# cslr_edma3cc register map
Vendor: Texas Instruments
Peripheral module from a debugger description file (folder TCI6484_C6457).
Registers are 32-bit, read-write, reset 0x0 unless marked. A register's access mark holds for its fields unless they carry their own. Offsets are as the file gives them; lines under a group give offsets from that group; [hi:lo] are bit positions; {n}, {i} and the like mark numbered series; 'fields as' and 'values as' point back to an identical list; <NAME> marks a mode.

## EDMA3CC — Enhanced DMA Channel Controller Module.
0x00 PID ro reset 0x40018B00 — Peripheral Revision
  [31:0] PID — Peripheral identifier uniquely identifies the EDMA3CC and the specific revision of the EDMA3CC
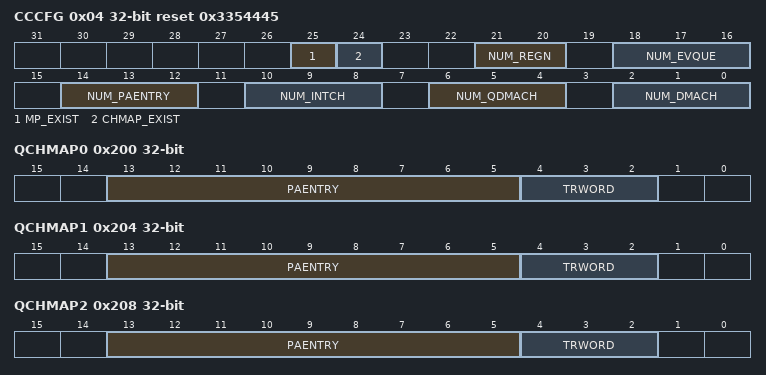
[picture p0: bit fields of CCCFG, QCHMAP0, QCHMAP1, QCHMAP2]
0x04 CCCFG access not given reset 0x3354445 — CC Configuration
  [25] MP_EXIST ro — Memory Protection Existence
    1=INCLUDED (Memory protection logic included)
  [24] CHMAP_EXIST ro — Channel Mapping Existence
    1=INCLUDED (Channel mapping logic included)
  [21:20] NUM_REGN ro — Number of MP and Shadow regions
    3=8 Regions
  [18:16] NUM_EVQUE ro — Number of Queues/Number of TCs
    5=6 TC/Event Queue
  [14:12] NUM_PAENTRY ro — Number of PaRAM entries
    4=256 Entries
  [10:8] NUM_INTCH ro — Number of Interrupt Channels
    4=64 Interrupt Channels
  [6:4] NUM_QDMACH ro — Number of QDMA Channels
    4=8 QDMA Channels
  [2:0] NUM_DMACH ro — Number of DMA Channels
    5=64 DMA Channels
0x100 DCHMAP0 access not given — DMA Channel Mapping to PaRAM{DCHMAP}
  [13:5] PAENTRY rw — Points to the PaRAM Entry number for the DMA Channel N
0x104 DCHMAP1 access not given — DMA Channel Mapping to PaRAM{DCHMAP}
  fields as DCHMAP0
0x108 DCHMAP2 access not given — DMA Channel Mapping to PaRAM{DCHMAP}
  fields as DCHMAP0
0x10C DCHMAP3 access not given — DMA Channel Mapping to PaRAM{DCHMAP}
  fields as DCHMAP0
0x110 DCHMAP4 access not given — DMA Channel Mapping to PaRAM{DCHMAP}
  fields as DCHMAP0
0x114 DCHMAP5 access not given — DMA Channel Mapping to PaRAM{DCHMAP}
  fields as DCHMAP0
0x118 DCHMAP6 access not given — DMA Channel Mapping to PaRAM{DCHMAP}
  fields as DCHMAP0
0x11C DCHMAP7 access not given — DMA Channel Mapping to PaRAM{DCHMAP}
  fields as DCHMAP0
0x120 DCHMAP8 access not given — DMA Channel Mapping to PaRAM{DCHMAP}
  fields as DCHMAP0
0x124 DCHMAP9 access not given — DMA Channel Mapping to PaRAM{DCHMAP}
  fields as DCHMAP0
0x128 DCHMAP10 access not given — DMA Channel Mapping to PaRAM{DCHMAP}
  fields as DCHMAP0
0x12C DCHMAP11 access not given — DMA Channel Mapping to PaRAM{DCHMAP}
  fields as DCHMAP0
0x130 DCHMAP12 access not given — DMA Channel Mapping to PaRAM{DCHMAP}
  fields as DCHMAP0
0x134 DCHMAP13 access not given — DMA Channel Mapping to PaRAM{DCHMAP}
  fields as DCHMAP0
0x138 DCHMAP14 access not given — DMA Channel Mapping to PaRAM{DCHMAP}
  fields as DCHMAP0
0x13C DCHMAP15 access not given — DMA Channel Mapping to PaRAM{DCHMAP}
  fields as DCHMAP0
0x140 DCHMAP16 access not given — DMA Channel Mapping to PaRAM{DCHMAP}
  fields as DCHMAP0
0x144 DCHMAP17 access not given — DMA Channel Mapping to PaRAM{DCHMAP}
  fields as DCHMAP0
0x148 DCHMAP18 access not given — DMA Channel Mapping to PaRAM{DCHMAP}
  fields as DCHMAP0
0x14C DCHMAP19 access not given — DMA Channel Mapping to PaRAM{DCHMAP}
  fields as DCHMAP0
0x150 DCHMAP20 access not given — DMA Channel Mapping to PaRAM{DCHMAP}
  fields as DCHMAP0
0x154 DCHMAP21 access not given — DMA Channel Mapping to PaRAM{DCHMAP}
  fields as DCHMAP0
0x158 DCHMAP22 access not given — DMA Channel Mapping to PaRAM{DCHMAP}
  fields as DCHMAP0
0x15C DCHMAP23 access not given — DMA Channel Mapping to PaRAM{DCHMAP}
  fields as DCHMAP0
0x160 DCHMAP24 access not given — DMA Channel Mapping to PaRAM{DCHMAP}
  fields as DCHMAP0
0x164 DCHMAP25 access not given — DMA Channel Mapping to PaRAM{DCHMAP}
  fields as DCHMAP0
0x168 DCHMAP26 access not given — DMA Channel Mapping to PaRAM{DCHMAP}
  fields as DCHMAP0
0x16C DCHMAP27 access not given — DMA Channel Mapping to PaRAM{DCHMAP}
  fields as DCHMAP0
0x170 DCHMAP28 access not given — DMA Channel Mapping to PaRAM{DCHMAP}
  fields as DCHMAP0
0x174 DCHMAP29 access not given — DMA Channel Mapping to PaRAM{DCHMAP}
  fields as DCHMAP0
0x178 DCHMAP30 access not given — DMA Channel Mapping to PaRAM{DCHMAP}
  fields as DCHMAP0
0x17C DCHMAP31 access not given — DMA Channel Mapping to PaRAM{DCHMAP}
  fields as DCHMAP0
0x180 DCHMAP32 access not given — DMA Channel Mapping to PaRAM{DCHMAP}
  fields as DCHMAP0
0x184 DCHMAP33 access not given — DMA Channel Mapping to PaRAM{DCHMAP}
  fields as DCHMAP0
0x188 DCHMAP34 access not given — DMA Channel Mapping to PaRAM{DCHMAP}
  fields as DCHMAP0
0x18C DCHMAP35 access not given — DMA Channel Mapping to PaRAM{DCHMAP}
  fields as DCHMAP0
0x190 DCHMAP36 access not given — DMA Channel Mapping to PaRAM{DCHMAP}
  fields as DCHMAP0
0x194 DCHMAP37 access not given — DMA Channel Mapping to PaRAM{DCHMAP}
  fields as DCHMAP0
0x198 DCHMAP38 access not given — DMA Channel Mapping to PaRAM{DCHMAP}
  fields as DCHMAP0
0x19C DCHMAP39 access not given — DMA Channel Mapping to PaRAM{DCHMAP}
  fields as DCHMAP0
0x1A0 DCHMAP40 access not given — DMA Channel Mapping to PaRAM{DCHMAP}
  fields as DCHMAP0
0x1A4 DCHMAP41 access not given — DMA Channel Mapping to PaRAM{DCHMAP}
  fields as DCHMAP0
0x1A8 DCHMAP42 access not given — DMA Channel Mapping to PaRAM{DCHMAP}
  fields as DCHMAP0
0x1AC DCHMAP43 access not given — DMA Channel Mapping to PaRAM{DCHMAP}
  fields as DCHMAP0
0x1B0 DCHMAP44 access not given — DMA Channel Mapping to PaRAM{DCHMAP}
  fields as DCHMAP0
0x1B4 DCHMAP45 access not given — DMA Channel Mapping to PaRAM{DCHMAP}
  fields as DCHMAP0
0x1B8 DCHMAP46 access not given — DMA Channel Mapping to PaRAM{DCHMAP}
  fields as DCHMAP0
0x1BC DCHMAP47 access not given — DMA Channel Mapping to PaRAM{DCHMAP}
  fields as DCHMAP0
0x1C0 DCHMAP48 access not given — DMA Channel Mapping to PaRAM{DCHMAP}
  fields as DCHMAP0
0x1C4 DCHMAP49 access not given — DMA Channel Mapping to PaRAM{DCHMAP}
  fields as DCHMAP0
0x1C8 DCHMAP50 access not given — DMA Channel Mapping to PaRAM{DCHMAP}
  fields as DCHMAP0
0x1CC DCHMAP51 access not given — DMA Channel Mapping to PaRAM{DCHMAP}
  fields as DCHMAP0
0x1D0 DCHMAP52 access not given — DMA Channel Mapping to PaRAM{DCHMAP}
  fields as DCHMAP0
0x1D4 DCHMAP53 access not given — DMA Channel Mapping to PaRAM{DCHMAP}
  fields as DCHMAP0
0x1D8 DCHMAP54 access not given — DMA Channel Mapping to PaRAM{DCHMAP}
  fields as DCHMAP0
0x1DC DCHMAP55 access not given — DMA Channel Mapping to PaRAM{DCHMAP}
  fields as DCHMAP0
0x1E0 DCHMAP56 access not given — DMA Channel Mapping to PaRAM{DCHMAP}
  fields as DCHMAP0
0x1E4 DCHMAP57 access not given — DMA Channel Mapping to PaRAM{DCHMAP}
  fields as DCHMAP0
0x1E8 DCHMAP58 access not given — DMA Channel Mapping to PaRAM{DCHMAP}
  fields as DCHMAP0
0x1EC DCHMAP59 access not given — DMA Channel Mapping to PaRAM{DCHMAP}
  fields as DCHMAP0
0x1F0 DCHMAP60 access not given — DMA Channel Mapping to PaRAM{DCHMAP}
  fields as DCHMAP0
0x1F4 DCHMAP61 access not given — DMA Channel Mapping to PaRAM{DCHMAP}
  fields as DCHMAP0
0x1F8 DCHMAP62 access not given — DMA Channel Mapping to PaRAM{DCHMAP}
  fields as DCHMAP0
0x1FC DCHMAP63 access not given — DMA Channel Mapping to PaRAM{DCHMAP}
  fields as DCHMAP0
0x200 QCHMAP0 access not given — QDMA Channel Mapping to PaRAM{QCHMAP}
  [13:5] PAENTRY rw — Points to the PaRAM Entry number for the QDMA Channel N
  [4:2] TRWORD rw — Points to the specific trigger word of the PaRAM set defined by PAENTRY. A write to the trigger word results in a QDMA event being recognized
0x204 QCHMAP1 access not given — QDMA Channel Mapping to PaRAM{QCHMAP}
  fields as QCHMAP0
0x208 QCHMAP2 access not given — QDMA Channel Mapping to PaRAM{QCHMAP}
  fields as QCHMAP0
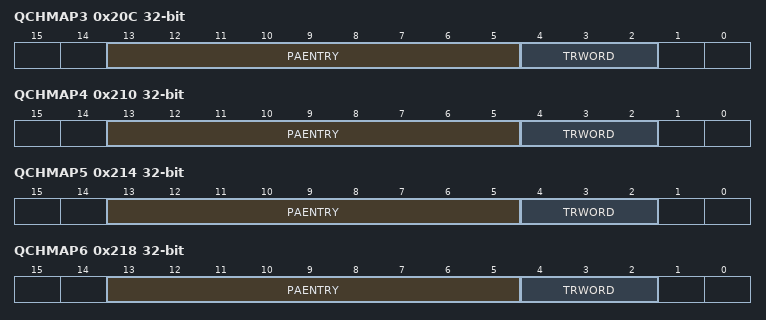
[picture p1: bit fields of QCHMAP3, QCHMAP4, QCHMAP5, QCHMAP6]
0x20C QCHMAP3 access not given — QDMA Channel Mapping to PaRAM{QCHMAP}
  fields as QCHMAP0
0x210 QCHMAP4 access not given — QDMA Channel Mapping to PaRAM{QCHMAP}
  fields as QCHMAP0
0x214 QCHMAP5 access not given — QDMA Channel Mapping to PaRAM{QCHMAP}
  fields as QCHMAP0
0x218 QCHMAP6 access not given — QDMA Channel Mapping to PaRAM{QCHMAP}
  fields as QCHMAP0
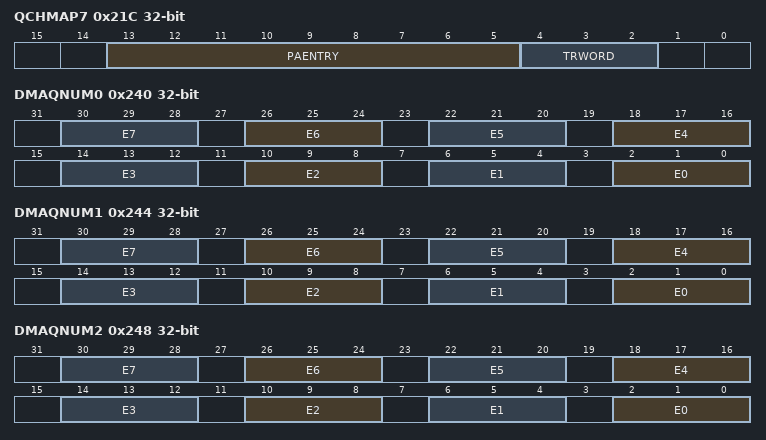
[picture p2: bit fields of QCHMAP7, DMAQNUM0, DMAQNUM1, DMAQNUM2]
0x21C QCHMAP7 access not given — QDMA Channel Mapping to PaRAM{QCHMAP}
  fields as QCHMAP0
0x240 DMAQNUM0 access not given — DMA Queue Number{DMAQNUM}
  [4n+2:4n] E{n} rw (n=0..7) — Event number = (ArrayIndex * 8) + {n}
0x244 DMAQNUM1 access not given — DMA Queue Number{DMAQNUM}
  [4n+2:4n] E{n} rw (n=0..7) — Event number = (ArrayIndex * 8) + {n}
0x248 DMAQNUM2 access not given — DMA Queue Number{DMAQNUM}
  [4n+2:4n] E{n} rw (n=0..7) — Event number = (ArrayIndex * 8) + {n}
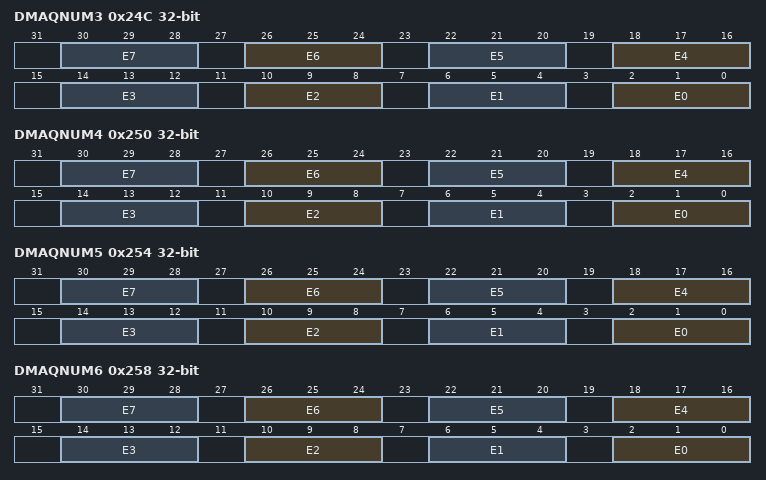
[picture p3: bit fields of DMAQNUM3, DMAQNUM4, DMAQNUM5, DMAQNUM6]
0x24C DMAQNUM3 access not given — DMA Queue Number{DMAQNUM}
  [4n+2:4n] E{n} rw (n=0..7) — Event number = (ArrayIndex * 8) + {n}
0x250 DMAQNUM4 access not given — DMA Queue Number{DMAQNUM}
  [4n+2:4n] E{n} rw (n=0..7) — Event number = (ArrayIndex * 8) + {n}
0x254 DMAQNUM5 access not given — DMA Queue Number{DMAQNUM}
  [4n+2:4n] E{n} rw (n=0..7) — Event number = (ArrayIndex * 8) + {n}
0x258 DMAQNUM6 access not given — DMA Queue Number{DMAQNUM}
  [4n+2:4n] E{n} rw (n=0..7) — Event number = (ArrayIndex * 8) + {n}
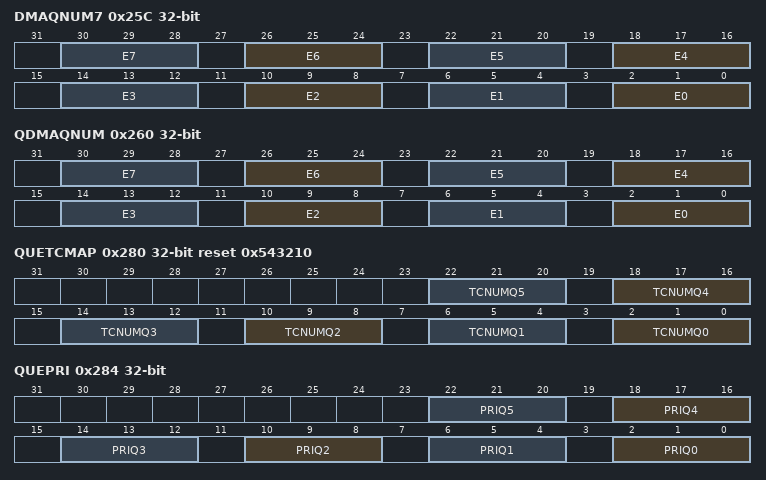
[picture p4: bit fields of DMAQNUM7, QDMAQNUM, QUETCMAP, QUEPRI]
0x25C DMAQNUM7 access not given — DMA Queue Number{DMAQNUM}
  [4n+2:4n] E{n} rw (n=0..7) — Event number = (ArrayIndex * 8) + {n}
0x260 QDMAQNUM access not given — QDMA Queue Number
  [4n+2:4n] E{n} rw (n=0..7) — Event number {n}
0x280 QUETCMAP access not given reset 0x543210 — Queue-to-TC Mapping Register
  [4n+2:4n] TCNUMQ{n} rw (n=0..5) — TC number for queue {n}.
0x284 QUEPRI access not given — Queue Priority
  [4n+2:4n] PRIQ{n} rw (n=0..5) — Priority level for Queue {n}
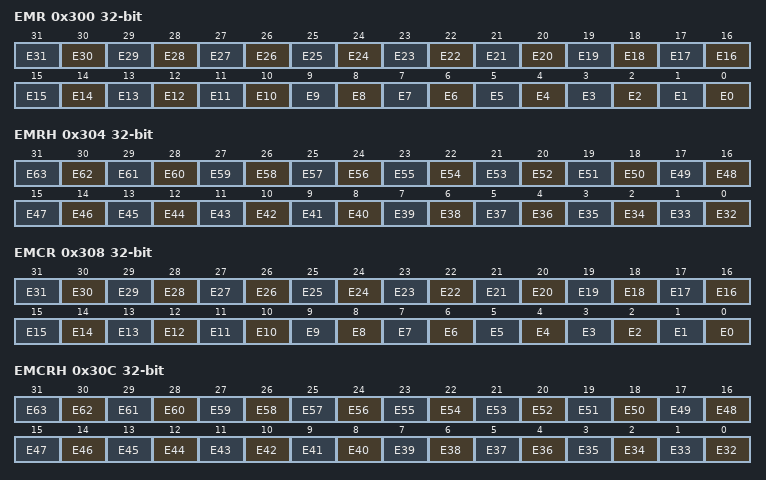
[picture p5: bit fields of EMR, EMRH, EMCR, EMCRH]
0x300 EMR ro — Event Miss Register
  [n] E{n} (n=0..31) — Event missed number {n}
0x304 EMRH ro — Event Miss Register High
  [n-32] E{n} (n=32..63) — Event missed number {n}
0x308 EMCR wo — Event Miss Clear Register
  [all] fields
    1=CLEAR
  [n] E{n} (n=0..31) — Event missed {n} clear
0x30C EMCRH wo — Event Miss Clear Register High
  [all] fields
    1=CLEAR
  [n-32] E{n} (n=32..63) — Event missed {n} clear
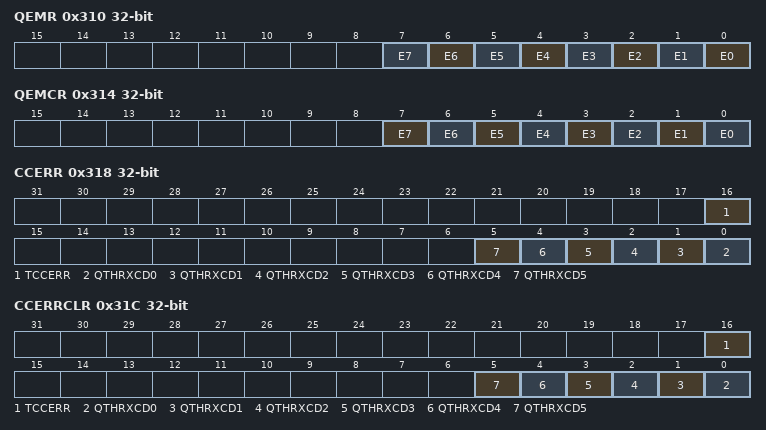
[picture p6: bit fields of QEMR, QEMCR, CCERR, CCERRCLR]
0x310 QEMR access not given — QDMA Event Miss Register
  [n] E{n} ro (n=0..7) — Event miss event {n}
0x314 QEMCR access not given — QDMA Event Miss Register
  [all] fields
    1=CLEAR
  [7] E7 wo — QDMA miss event 7clear
  [n] E{n} wo (n=0..6) — QDMA miss event {n} clear
0x318 CCERR access not given — CC Error Register
  [16] TCCERR ro — Transfer completion code error
  [n] QTHRXCD{n} ro (n=0..5) — Queue Threshold Error for Queue {n}
0x31C CCERRCLR access not given — CC Error Clear Register
  [all] fields
    1=CLEAR
  [16] TCCERR wo — Transfer completion code error clear
  [n] QTHRXCD{n} wo (n=0..5) — Queue Threshold Error Clear for Queue {n}
0x320 EEVAL access not given — Error Evaluation Register
  [0] EVAL wo — Error interrupt Evaluate
    1=EVAL (Error Interrupt Evaluate)
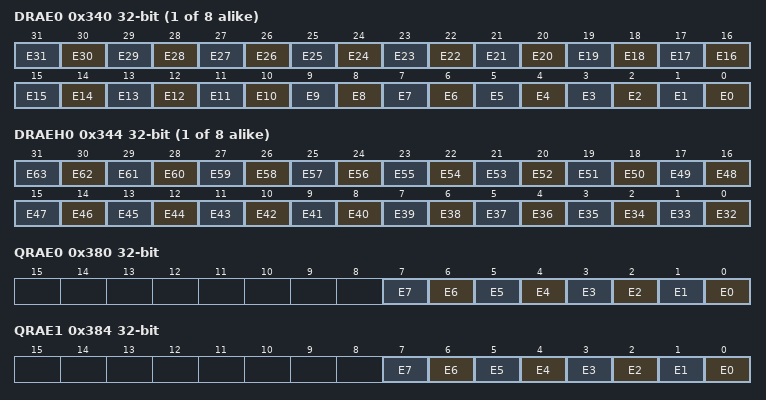
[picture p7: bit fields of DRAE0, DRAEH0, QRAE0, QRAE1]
{0x340+8i} DRAE{i} (i=0..7) — DMA Region Access Enable
  [n] E{n} (n=0..31) — DMA region access enable for bit {n}/channel {n} in region m (m = 0 to 7)
{0x344+8i} DRAEH{i} (i=0..7) — DMA Region Access Enable High
  [n-32] E{n} (n=32..63) — DMA region access enable for bit {n}/channel {n} in region m (m = 0 to 7)
0x380 QRAE0 access not given — QDMA Region Access Enable{QRAE}
  [n] E{n} rw (n=0..7) — QDMA region access enable for bit {n}/channel {n} in region m (m = 0 to 7)
0x384 QRAE1 access not given — QDMA Region Access Enable{QRAE}
  fields as QRAE0
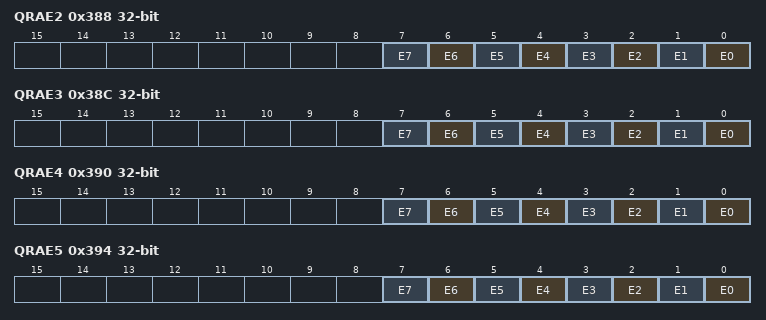
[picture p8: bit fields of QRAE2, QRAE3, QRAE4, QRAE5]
0x388 QRAE2 access not given — QDMA Region Access Enable{QRAE}
  fields as QRAE0
0x38C QRAE3 access not given — QDMA Region Access Enable{QRAE}
  fields as QRAE0
0x390 QRAE4 access not given — QDMA Region Access Enable{QRAE}
  fields as QRAE0
0x394 QRAE5 access not given — QDMA Region Access Enable{QRAE}
  fields as QRAE0
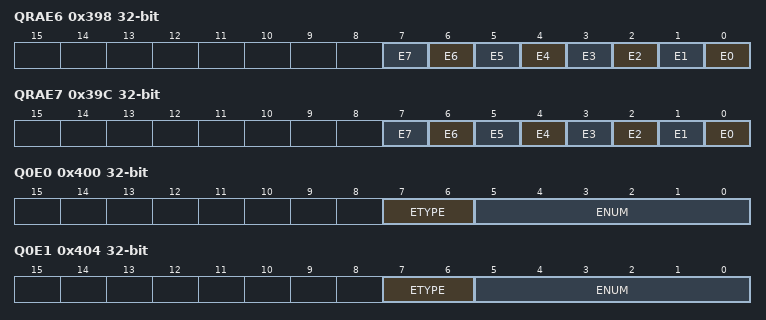
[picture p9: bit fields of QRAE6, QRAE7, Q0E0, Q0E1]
0x398 QRAE6 access not given — QDMA Region Access Enable{QRAE}
  fields as QRAE0
0x39C QRAE7 access not given — QDMA Region Access Enable{QRAE}
  fields as QRAE0
0x400 Q0E0 ro — Event Entry{EVT_ENTRY}
  [7:6] ETYPE — Event Type
    0=EVENT (Event Triggered via ER); 1=MANUAL (Manual Triggered via ESR); 2=CHAIN (Chain Triggered via CER); 3=AUTO (Auto Triggered via QER)
  [5:0] ENUM — Event Number (0-63)/(0-7)
0x404 Q0E1 ro — Event Entry{EVT_ENTRY}
  fields as Q0E0
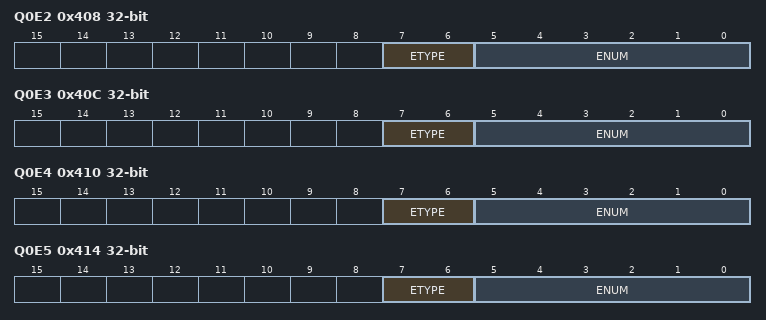
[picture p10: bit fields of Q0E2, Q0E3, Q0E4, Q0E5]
0x408 Q0E2 ro — Event Entry{EVT_ENTRY}
  fields as Q0E0
0x40C Q0E3 ro — Event Entry{EVT_ENTRY}
  fields as Q0E0
0x410 Q0E4 ro — Event Entry{EVT_ENTRY}
  fields as Q0E0
0x414 Q0E5 ro — Event Entry{EVT_ENTRY}
  fields as Q0E0
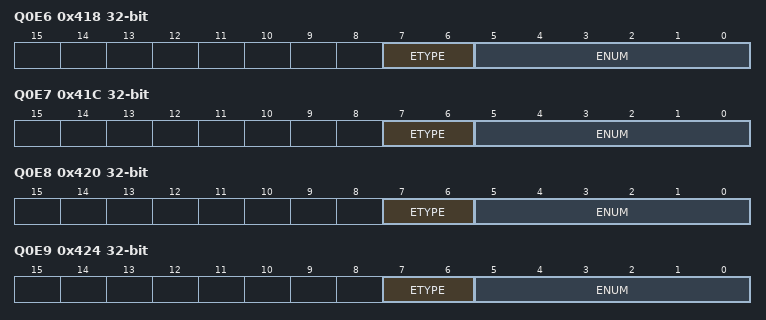
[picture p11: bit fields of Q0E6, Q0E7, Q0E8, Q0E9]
0x418 Q0E6 ro — Event Entry{EVT_ENTRY}
  fields as Q0E0
0x41C Q0E7 ro — Event Entry{EVT_ENTRY}
  fields as Q0E0
0x420 Q0E8 ro — Event Entry{EVT_ENTRY}
  fields as Q0E0
0x424 Q0E9 ro — Event Entry{EVT_ENTRY}
  fields as Q0E0
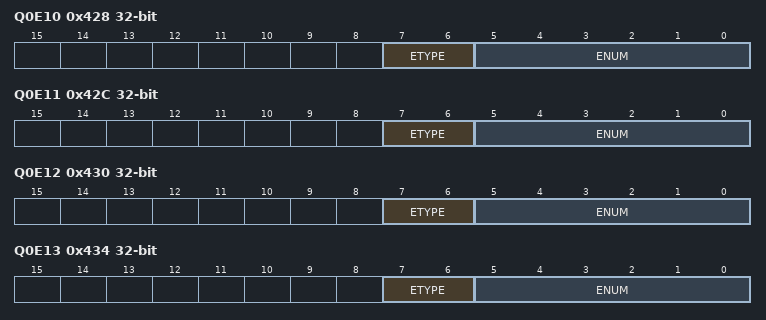
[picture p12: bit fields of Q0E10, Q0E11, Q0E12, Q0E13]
0x428 Q0E10 ro — Event Entry{EVT_ENTRY}
  fields as Q0E0
0x42C Q0E11 ro — Event Entry{EVT_ENTRY}
  fields as Q0E0
0x430 Q0E12 ro — Event Entry{EVT_ENTRY}
  fields as Q0E0
0x434 Q0E13 ro — Event Entry{EVT_ENTRY}
  fields as Q0E0
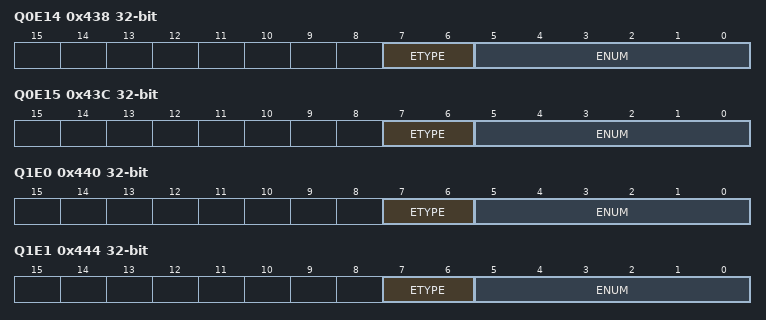
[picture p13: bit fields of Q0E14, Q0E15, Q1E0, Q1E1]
0x438 Q0E14 ro — Event Entry{EVT_ENTRY}
  fields as Q0E0
0x43C Q0E15 ro — Event Entry{EVT_ENTRY}
  fields as Q0E0
0x440 Q1E0 ro — Event Entry{EVT_ENTRY}
  fields as Q0E0
0x444 Q1E1 ro — Event Entry{EVT_ENTRY}
  fields as Q0E0
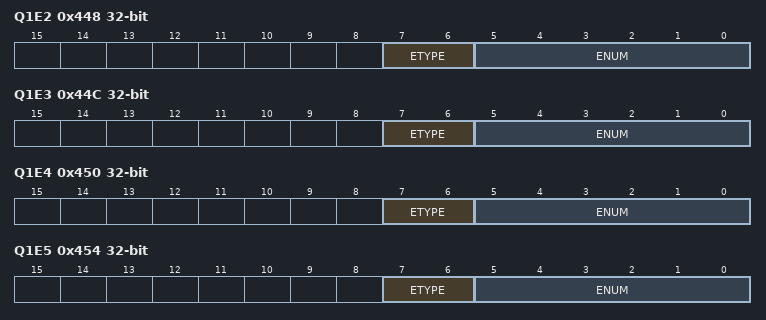
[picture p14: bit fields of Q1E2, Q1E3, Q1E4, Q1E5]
0x448 Q1E2 ro — Event Entry{EVT_ENTRY}
  fields as Q0E0
0x44C Q1E3 ro — Event Entry{EVT_ENTRY}
  fields as Q0E0
0x450 Q1E4 ro — Event Entry{EVT_ENTRY}
  fields as Q0E0
0x454 Q1E5 ro — Event Entry{EVT_ENTRY}
  fields as Q0E0
0x458 Q1E6 ro — Event Entry{EVT_ENTRY}
  fields as Q0E0
0x45C Q1E7 ro — Event Entry{EVT_ENTRY}
  fields as Q0E0
0x460 Q1E8 ro — Event Entry{EVT_ENTRY}
  fields as Q0E0
0x464 Q1E9 ro — Event Entry{EVT_ENTRY}
  fields as Q0E0
0x468 Q1E10 ro — Event Entry{EVT_ENTRY}
  fields as Q0E0
0x46C Q1E11 ro — Event Entry{EVT_ENTRY}
  fields as Q0E0
0x470 Q1E12 ro — Event Entry{EVT_ENTRY}
  fields as Q0E0
0x474 Q1E13 ro — Event Entry{EVT_ENTRY}
  fields as Q0E0
0x478 Q1E14 ro — Event Entry{EVT_ENTRY}
  fields as Q0E0
0x47C Q1E15 ro — Event Entry{EVT_ENTRY}
  fields as Q0E0
0x480 Q2E0 ro — Event Entry{EVT_ENTRY}
  fields as Q0E0
0x484 Q2E1 ro — Event Entry{EVT_ENTRY}
  fields as Q0E0
0x488 Q2E2 ro — Event Entry{EVT_ENTRY}
  fields as Q0E0
0x48C Q2E3 ro — Event Entry{EVT_ENTRY}
  fields as Q0E0
0x490 Q2E4 ro — Event Entry{EVT_ENTRY}
  fields as Q0E0
0x494 Q2E5 ro — Event Entry{EVT_ENTRY}
  fields as Q0E0
0x498 Q2E6 ro — Event Entry{EVT_ENTRY}
  fields as Q0E0
0x49C Q2E7 ro — Event Entry{EVT_ENTRY}
  fields as Q0E0
0x4A0 Q2E8 ro — Event Entry{EVT_ENTRY}
  fields as Q0E0
0x4A4 Q2E9 ro — Event Entry{EVT_ENTRY}
  fields as Q0E0
0x4A8 Q2E10 ro — Event Entry{EVT_ENTRY}
  fields as Q0E0
0x4AC Q2E11 ro — Event Entry{EVT_ENTRY}
  fields as Q0E0
0x4B0 Q2E12 ro — Event Entry{EVT_ENTRY}
  fields as Q0E0
0x4B4 Q2E13 ro — Event Entry{EVT_ENTRY}
  fields as Q0E0
0x4B8 Q2E14 ro — Event Entry{EVT_ENTRY}
  fields as Q0E0
0x4BC Q2E15 ro — Event Entry{EVT_ENTRY}
  fields as Q0E0
0x4C0 Q3E0 ro — Event Entry{EVT_ENTRY}
  fields as Q0E0
0x4C4 Q3E1 ro — Event Entry{EVT_ENTRY}
  fields as Q0E0
0x4C8 Q3E2 ro — Event Entry{EVT_ENTRY}
  fields as Q0E0
0x4CC Q3E3 ro — Event Entry{EVT_ENTRY}
  fields as Q0E0
0x4D0 Q3E4 ro — Event Entry{EVT_ENTRY}
  fields as Q0E0
0x4D4 Q3E5 ro — Event Entry{EVT_ENTRY}
  fields as Q0E0
0x4D8 Q3E6 ro — Event Entry{EVT_ENTRY}
  fields as Q0E0
0x4DC Q3E7 ro — Event Entry{EVT_ENTRY}
  fields as Q0E0
0x4E0 Q3E8 ro — Event Entry{EVT_ENTRY}
  fields as Q0E0
0x4E4 Q3E9 ro — Event Entry{EVT_ENTRY}
  fields as Q0E0
0x4E8 Q3E10 ro — Event Entry{EVT_ENTRY}
  fields as Q0E0
0x4EC Q3E11 ro — Event Entry{EVT_ENTRY}
  fields as Q0E0
0x4F0 Q3E12 ro — Event Entry{EVT_ENTRY}
  fields as Q0E0
0x4F4 Q3E13 ro — Event Entry{EVT_ENTRY}
  fields as Q0E0
0x4F8 Q3E14 ro — Event Entry{EVT_ENTRY}
  fields as Q0E0
0x4FC Q3E15 ro — Event Entry{EVT_ENTRY}
  fields as Q0E0
0x500 Q4E0 ro — Event Entry{EVT_ENTRY}
  fields as Q0E0
0x504 Q4E1 ro — Event Entry{EVT_ENTRY}
  fields as Q0E0
0x508 Q4E2 ro — Event Entry{EVT_ENTRY}
  fields as Q0E0
0x50C Q4E3 ro — Event Entry{EVT_ENTRY}
  fields as Q0E0
0x510 Q4E4 ro — Event Entry{EVT_ENTRY}
  fields as Q0E0
0x514 Q4E5 ro — Event Entry{EVT_ENTRY}
  fields as Q0E0
0x518 Q4E6 ro — Event Entry{EVT_ENTRY}
  fields as Q0E0
0x51C Q4E7 ro — Event Entry{EVT_ENTRY}
  fields as Q0E0
0x520 Q4E8 ro — Event Entry{EVT_ENTRY}
  fields as Q0E0
0x524 Q4E9 ro — Event Entry{EVT_ENTRY}
  fields as Q0E0
0x528 Q4E10 ro — Event Entry{EVT_ENTRY}
  fields as Q0E0
0x52C Q4E11 ro — Event Entry{EVT_ENTRY}
  fields as Q0E0
0x530 Q4E12 ro — Event Entry{EVT_ENTRY}
  fields as Q0E0
0x534 Q4E13 ro — Event Entry{EVT_ENTRY}
  fields as Q0E0
0x538 Q4E14 ro — Event Entry{EVT_ENTRY}
  fields as Q0E0
0x53C Q4E15 ro — Event Entry{EVT_ENTRY}
  fields as Q0E0
0x540 Q5E0 ro — Event Entry{EVT_ENTRY}
  fields as Q0E0
0x544 Q5E1 ro — Event Entry{EVT_ENTRY}
  fields as Q0E0
0x548 Q5E2 ro — Event Entry{EVT_ENTRY}
  fields as Q0E0
0x54C Q5E3 ro — Event Entry{EVT_ENTRY}
  fields as Q0E0
0x550 Q5E4 ro — Event Entry{EVT_ENTRY}
  fields as Q0E0
0x554 Q5E5 ro — Event Entry{EVT_ENTRY}
  fields as Q0E0
0x558 Q5E6 ro — Event Entry{EVT_ENTRY}
  fields as Q0E0
0x55C Q5E7 ro — Event Entry{EVT_ENTRY}
  fields as Q0E0
0x560 Q5E8 ro — Event Entry{EVT_ENTRY}
  fields as Q0E0
0x564 Q5E9 ro — Event Entry{EVT_ENTRY}
  fields as Q0E0
0x568 Q5E10 ro — Event Entry{EVT_ENTRY}
  fields as Q0E0
0x56C Q5E11 ro — Event Entry{EVT_ENTRY}
  fields as Q0E0
0x570 Q5E12 ro — Event Entry{EVT_ENTRY}
  fields as Q0E0
0x574 Q5E13 ro — Event Entry{EVT_ENTRY}
  fields as Q0E0
0x578 Q5E14 ro — Event Entry{EVT_ENTRY}
  fields as Q0E0
0x57C Q5E15 ro — Event Entry{EVT_ENTRY}
  fields as Q0E0
0x600 QSTAT0 access not given — Queue Status{QSTAT}
  [24] THRXD ro — Threshold Exceeded
    0=NOTEXCEED (Not Exceeded); 1=EXCEED (Exceeded)
  [20:16] WM ro — Watermark for Maximum Queue Usage
    0=EMPTY (Empty Queue); 22=FULL (Full Queue)
  [12:8] NUMVAL ro — Number of Valid Entries in Queue
  [3:0] STRTPTR ro — Start Pointer
0x604 QSTAT1 access not given — Queue Status{QSTAT}
  fields as QSTAT0
0x608 QSTAT2 access not given — Queue Status{QSTAT}
  fields as QSTAT0
0x60C QSTAT3 access not given — Queue Status{QSTAT}
  fields as QSTAT0
0x610 QSTAT4 access not given — Queue Status{QSTAT}
  fields as QSTAT0
0x614 QSTAT5 access not given — Queue Status{QSTAT}
  fields as QSTAT0
0x620 QWMTHRA access not given reset 0x10101010 — Queue Watermark Threshold A Register
  [all] fields
    23=DISABLE (Disable threshold errors)
  [8n+4:8n] Q{n} rw (n=0..3) — Queue threshold for queue {n} value
0x624 QWMTHRb access not given reset 0x1010 — Queue Watermark Threshold B Register
  [12:8] Q5 rw — Queue threshold for queue 5 value
    23=DISABLE (Disable threshold errors)
  [4:0] Q4 rw — Queue threshold for queue 4 value
    23=DISABLE (Disable threshold errors)
0x640 CCSTAT access not given — Channel Controller Status
  [n+16] QUEACTV{n} ro (n=0..5) — Queue {n} Active
    0=NONE; 1=ACTIVE
  [13:8] COMPACTV ro — Completion Request Active
    0=NONE
  [7:5] _RESV_10 — (access N)
  [4] ACTV ro — Channel Controller Active
    0=IDLE; 1=BUSY
  [3] WSTATACTV ro — Write Status iterface Active
    0=IDLE; 1=BUSY
  [2] TRACTV ro — Transfer Request Active
    0=NONE; 1=ACTIVE
  [1] QEVTACTV ro — QDMA Event Active
    0=NONE; 1=ACTIVE
  [0] EVTACTV ro — DMA Event Active
    0=NONE; 1=ACTIVE
0x800 MPFAR ro — Memory Protect Fault address
  [31:0] FADDR — Fault Address
0x804 MPFSR access not given reset 0x1200 — Memory Protect Fault Status
  [12:9] FID ro — Faulted ID
  [5] SRE ro — Supervisor Read Error
  [4] SWE ro — Supervisor Write Error
  [3] SXE ro — Supervisor Executer Error
  [2] URE ro — User Read Error
  [1] UWE ro — User Write Error
  [0] UXE ro — User Execute Error
0x808 MPFCR access not given — Memory Protect Fault Command
  [0] MPFCLR wo — Fault Clear register
0x80C MPPAG access not given reset 0xFEF6 — MP Permission attribute for Gbl Regs
  [n+10] AID{n} rw (n=0..5) — Allowed ID {n}
    0=BLOCK (Block requests with privID = {n}); 1=PERMIT (Permit requests with privID = {n})
  [9] EXT rw — External allowed ID
    0=BLOCK (Block requests with privID >= 6); 1=PERMIT (Permit requests with privID >= 6)
  [5] SR rw — Supervisor Read permissions
    0=BLOCK (Read accesses not allowed in this region); 1=PERMIT (Read accesses allowed in this region)
  [4] SW rw — Supervisor Write permissions
    0=BLOCK (Write accesses not allowed in this region); 1=PERMIT (Write accesses allowed in this region)
  [3] SX rw — Supervisor Execute permissions
    0=BLOCK (Execute accesses not allowed in this region); 1=PERMIT (Execute accesses allowed in this region)
  [2] UR rw — User Read permissions
    values as SR
  [1] UW rw — User Write permissions
    values as SW
  [0] UX rw — User Execute permissions
    values as SX
0x810 MPPA0 access not given reset 0xFEF6 — MP Permission attribute for DMA Regs{MPPA}
  fields as MPPAG
0x814 MPPA1 access not given reset 0xFEF6 — MP Permission attribute for DMA Regs{MPPA}
  fields as MPPAG
0x818 MPPA2 access not given reset 0xFEF6 — MP Permission attribute for DMA Regs{MPPA}
  fields as MPPAG
0x81C MPPA3 access not given reset 0xFEF6 — MP Permission attribute for DMA Regs{MPPA}
  fields as MPPAG
0x820 MPPA4 access not given reset 0xFEF6 — MP Permission attribute for DMA Regs{MPPA}
  fields as MPPAG
0x824 MPPA5 access not given reset 0xFEF6 — MP Permission attribute for DMA Regs{MPPA}
  fields as MPPAG
0x828 MPPA6 access not given reset 0xFEF6 — MP Permission attribute for DMA Regs{MPPA}
  fields as MPPAG
0x82C MPPA7 access not given reset 0xFEF6 — MP Permission attribute for DMA Regs{MPPA}
  fields as MPPAG
0x1000 ER ro — Event Register
  [n] E{n} (n=0..31) — Event {n}
0x1004 ERH ro — Event Register High
  [n-32] E{n} (n=32..63) — Event {n}
0x1008 ECR wo — Event Clear Register
  [all] fields
    1=CLEAR
  [n] E{n} (n=0..31) — Event clear for event {n}
0x100C ECRH wo — Event Clear Register High
  [all] fields
    1=CLEAR
  [n-32] E{n} (n=32..63) — Event clear for event {n}
0x1010 ESR — Event Set Register
  [all] fields
    1=SET
  [n] E{n} (n=0..31) — Event set for event {n}
0x1014 ESRH — Event Set Register High
  [all] fields
    1=SET
  [n-32] E{n} (n=32..63) — Event set for event {n}
0x1018 CER ro — Chained Event Register
  [n] E{n} (n=0..31) — Chained event for event {n}
0x101C CERH ro — Chained Event Register High
  [n-32] E{n} (n=32..63) — Chained event for event {n}
0x1020 EER ro — Event Enable Register
  [31] E31 — Event enable for events 31
    1=?
  [n] E{n} (n=0..30) — Event enable for events {n}
0x1024 EERH ro — Event Enable Register High
  [n-32] E{n} (n=32..63) — Event enable for events {n}
0x1028 EECR wo — Event Enable Clear Register
  [all] fields
    1=CLEAR
  [n] E{n} (n=0..31) — Event enable clear for events {n}
0x102C EECRH wo — Event Enable Clear Register High
  [all] fields
    1=CLEAR
  [n-32] E{n} (n=32..63) — Event enable clear for events {n}
0x1030 EESR wo — Event Enable Set Register
  [all] fields
    1=SET
  [n] E{n} (n=0..31) — Event enable set for events {n}
0x1034 EESRH wo — Event Enable Set Register High
  [all] fields
    1=SET
  [n-32] E{n} (n=32..63) — Event enable set for events {n}
0x1038 SER ro — Secondary Event Register
  [n] E{n} (n=0..31) — Event {n}
0x103C SERH ro — Secondary Event Register High
  [n-32] E{n} (n=32..63) — Event {n}
0x1040 SECR wo — Secondary Event Clear Register
  [all] fields
    1=CLEAR
  [n] E{n} (n=0..31) — Secondary event clear for event {n}
0x1044 SECRH wo — Secondary Event Clear Register High
  [all] fields
    1=CLEAR
  [n-32] E{n} (n=32..63) — Secondary event clear for event {n}
0x1050 IER ro — Interrupt Enable Register
  [n] I{n} (n=0..31) — Interrupt enable for channels {n}
0x1054 IERH ro — Interrupt Enable Register High
  [n-32] I{n} (n=32..63) — Interrupt enable for channels {n}
0x1058 IECR wo — Interrupt Enable Clear Register
  [all] fields
    1=CLEAR
  [n] I{n} (n=0..31) — Interrupt enable clear for channels {n}
0x105C IECRH wo — Interrupt Enable Clear Register High
  [all] fields
    1=CLEAR
  [n-32] I{n} (n=32..63) — Interrupt enable clear for channels {n}
0x1060 IESR wo — Interrupt Enable Set Register
  [all] fields
    1=SET
  [n] I{n} (n=0..31) — Interrupt enable set for channels {n}
0x1064 IESRH wo — Interrupt Enable Set Register High
  [all] fields
    1=SET
  [n-32] I{n} (n=32..63) — Interrupt enable set for channels {n}
0x1068 IPR ro — Interrupt Pending Register
  [n] I{n} (n=0..31) — Interrupt pending for TCC = {n}
0x106C IPRH ro — Interrupt Pending Register High
  [n-32] I{n} (n=32..63) — Interrupt pending for TCC = {n}
0x1070 ICR wo — Interrupt Clear Register
  [all] fields
    1=CLEAR
  [n] I{n} (n=0..31) — Interrupt clear for TCC = {n}
0x1074 ICRH wo — Interrupt Clear Register High
  [all] fields
    1=CLEAR
  [n-32] I{n} (n=32..63) — Interrupt clear for TCC = {n}
0x1078 IEVAL access not given — Interrupt Eval Register
  [0] EVAL wo — Interrupt Evaluate
    1=EVAL (Causes Completion interrupt output to be pulsed is any enabled IERn and IPRn pending)
0x1080 QER access not given — QDMA Event Register
  [n] E{n} ro (n=0..7) — QDMA event for channels {n}
0x1084 QEER access not given — QDMA Event Enable Register
  [n] E{n} ro (n=0..7) — QDMA event enable for channels {n}
0x1088 QEECR access not given — QDMA Event Enable Clear Register
  [all] fields
    1=CLEAR
  [n] E{n} wo (n=0..7) — QDMA event enable clear for channels {n}
0x108C QEESR access not given — QDMA Event Enable Set Register
  [all] fields
    1=SET
  [n] E{n} wo (n=0..7) — QDMA event enable set for channels {n}
0x1090 QSER access not given — QDMA Secondary Event Register
  [n] E{n} ro (n=0..7) — QDMA secondary event for channels {n}
0x1094 QSECR access not given — QDMA Secondary Event Clear Register
  [all] fields
    1=CLEAR
  [n] E{n} wo (n=0..7) — QDMA secondary event clear for channels {n}
{0x2000+0x200*i} ER{i} ro (i=0..7) — Event Register
  [31:0] REG
{0x2004+0x200*i} ERH{i} ro (i=0..7) — Event Register High
  [31:0] REG
{0x2008+0x200*i} ECR{i} wo (i=0..7) — Event Clear Register
  [31:0] REG
{0x200C+0x200*i} ECRH{i} wo (i=0..7) — Event Clear Register High
  [31:0] REG
{0x2010+0x200*i} ESR{i} wo (i=0..7) — Event Set Register
  [31:0] REG
{0x2014+0x200*i} ESRH{i} wo (i=0..7) — Event Set Register High
  [31:0] REG
{0x2018+0x200*i} CER{i} ro (i=0..7) — Chained Event Register
  [31:0] REG
{0x201C+0x200*i} CERH{i} ro (i=0..7) — Chained Event Register High
  [31:0] REG
{0x2020+0x200*i} EER{i} ro (i=0..7) — Event Enable Register
  [31:0] REG
{0x2024+0x200*i} EERH{i} ro (i=0..7) — Event Enable Register High
  [31:0] REG
{0x2028+0x200*i} EECR{i} wo (i=0..7) — Event Enable Clear Register
  [31:0] REG
{0x202C+0x200*i} EECRH{i} wo (i=0..7) — Event Enable Clear Register High
  [31:0] REG
{0x2030+0x200*i} EESR{i} wo (i=0..7) — Event Enable Set Register
  [31:0] REG
{0x2034+0x200*i} EESRH{i} wo (i=0..7) — Event Enable Set Register High
  [31:0] REG
{0x2038+0x200*i} SER{i} ro (i=0..7) — Secondary Event Register
  [31:0] REG
{0x203C+0x200*i} SERH{i} ro (i=0..7) — Secondary Event Register High
  [31:0] REG
{0x2040+0x200*i} SECR{i} wo (i=0..7) — Secondary Event Clear Register
  [31:0] REG
{0x2044+0x200*i} SECRH{i} wo (i=0..7) — Secondary Event Clear Register High
  [31:0] REG
{0x2050+0x200*i} IER{i} ro (i=0..7) — Interrupt Enable Register
  [31:0] REG
{0x2054+0x200*i} IERH{i} ro (i=0..7) — Interrupt Enable Register High
  [31:0] REG
{0x2058+0x200*i} IECR{i} wo (i=0..7) — Interrupt Enable Clear Register
  [31:0] REG
{0x205C+0x200*i} IECRH{i} wo (i=0..7) — Interrupt Enable Clear Register High
  [31:0] REG
{0x2060+0x200*i} IESR{i} wo (i=0..7) — Interrupt Enable Set Register
  [31:0] REG
{0x2064+0x200*i} IESRH{i} wo (i=0..7) — Interrupt Enable Set Register High
  [31:0] REG
{0x2068+0x200*i} IPR{i} ro (i=0..7) — Interrupt Pending Register
  [31:0] REG
{0x206C+0x200*i} IPRH{i} ro (i=0..7) — Interrupt Pending Register High
  [31:0] REG
{0x2070+0x200*i} ICR{i} wo (i=0..7) — Interrupt Clear Register
  [31:0] REG
{0x2074+0x200*i} ICRH{i} wo (i=0..7) — Interrupt Clear Register High
  [31:0] REG
{0x2078+0x200*i} IEVAL{i} access not given (i=0..7) — Interrupt Eval Register
  [0] EVAL wo — Interrupt Evaluate
    1=EVAL (Causes Region interrupt output to be pulsed is any enabled IERn and IPRn pending also masked by DRAEn)
{0x2080+0x200*i} QER{i} ro (i=0..7) — QDMA Event Register
  [31:0] REG
{0x2084+0x200*i} QEER{i} ro (i=0..7) — QDMA Event Enable Register
  [31:0] REG
{0x2088+0x200*i} QEECR{i} wo (i=0..7) — QDMA Event Enable Clear Register
  [31:0] REG
{0x208C+0x200*i} QEESR{i} wo (i=0..7) — QDMA Event Enable Set Register
  [31:0] REG
{0x2090+0x200*i} QSER{i} ro (i=0..7) — QDMA Secondary Event Register
  [31:0] REG
{0x2094+0x200*i} QSECR{i} wo (i=0..7) — QDMA Secondary Event Clear Register
  [31:0] REG
{0x4000+0x20*i} OPT{i} access not given (i=0..255) — Option
  [31] PRIV ro — Privilege level (supervisor versus user) for the host/CPU/DMA that programmed this PaRAM set
    0=USER (User level privilege); 1=SUPERVISOR (Supervisor level privilege)
  [27:24] PRIVID ro — Privilege ID for external host/cpu/dma
  [23] ITCCHEN rw — Intermediate transfer completion chaining enable
    0=DISABLE (ITCC Disabled); 1=ENABLE (ITCC Enabled)
  [22] TCCHEN rw — Transfer completion chaining enable
    0=DISABLE (TCC Disabled); 1=ENABLE (TCC Enabled)
  [21] ITCINTEN rw — Intermediate transfer completion interrupt enable
    0=DISABLE; 1=ENABLE
  [20] TCINTEN rw — Transfer completion interrupt enable
    0=DISABLE; 1=ENABLE
  [17:12] TCC rw — Transfer completion code
  [11] TCCMODE rw — Transfer completion mode
    0=NORMAL; 1=EARLY
  [10:8] FWID rw — Fifo Width
    0=8; 1=16; 2=32; 3=64; 4=128; 5=256
  [3] STATIC rw — Static set
    0=NORMAL; 1=STATIC
  [2] SYNCDIM rw — Transfer Synchronization Dimension
    0=ASYNC; 1=ABSYNC
  [1] DAM rw — Destination address mode
    0=INCR; 1=CONST
  [0] SAM rw — Source address mode
    0=INCR; 1=CONST
{0x4004+0x20*i} SRC{i} (i=0..255) — Source Address
  [31:0] SRC
{0x4008+0x20*i} A_B_CNT{i} (i=0..255) — A Count
  [31:16] BCNT — B Count
  [15:0] ACNT — A Count
{0x400C+0x20*i} DST{i} (i=0..255) — Destination Address
  [31:0] DST
{0x4010+0x20*i} SRC_DST_BIDX{i} (i=0..255) — SRC B Index, DST B Index
  [31:16] DSTBIDX — Destination B Index
  [15:0] SRCBIDX — Source B Index
{0x4014+0x20*i} LINK_BCNTRLD{i} (i=0..255) — Link Address
  [31:16] BCNTRLD — B Count Reload
  [15:0] LINK — Link Address
{0x4018+0x20*i} SRC_DST_CIDX{i} (i=0..255) — Source C Index
  [31:16] DSTCIDX — Destination C Index
  [15:0] SRCCIDX — Source C Index
{0x401C+0x20*i} CCNT{i} access not given (i=0..255) — C Count
  [15:0] CCNT rw — C Counter
